# CLK2_STATCOLL3 register map
Vendor: Texas Instruments
Peripheral module from a debugger description file (folder DRA74xP_75xP_76xP_77xP).
Registers are 32-bit, access per field, reset 0x0 unless marked. A register's access mark holds for its fields unless they carry their own. Offsets are as the file gives them; lines under a group give offsets from that group; [hi:lo] are bit positions; {n}, {i} and the like mark numbered series; 'fields as' and 'values as' point back to an identical list; <NAME> marks a mode.

## CLK2_STATCOLL3
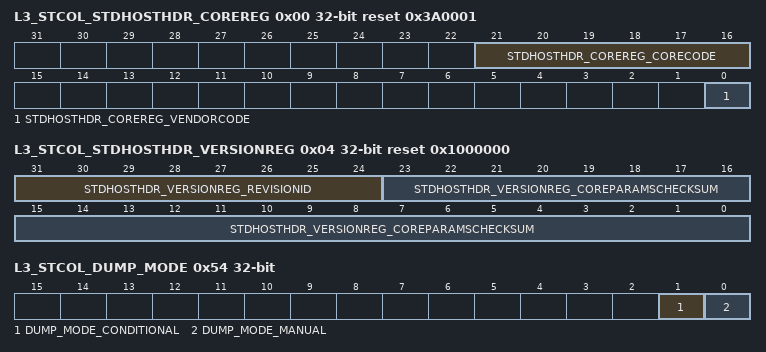
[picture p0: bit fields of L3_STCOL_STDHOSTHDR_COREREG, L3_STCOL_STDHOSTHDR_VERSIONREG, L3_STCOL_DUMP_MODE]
0x00 L3_STCOL_STDHOSTHDR_COREREG access not given reset 0x3A0001
  [21:16] STDHOSTHDR_COREREG_CORECODE ro — The Core Code field is a constant reporting a vendor-specific core generator code. Type: Constant. Reset value: 0x3A. (When the instance is CLK3_FLAGMUX_STATCOLL reset value is 0x37)
  [0] STDHOSTHDR_COREREG_VENDORCODE — The Vendor Code field is a constant reporting the core generator vendor code. Type: Constant. Reset value: 0x1. (access R1)
    0=Third-party_vendor; 1=STDHOSTHDR_COREREG_VENDORCODE_1_r
0x04 L3_STCOL_STDHOSTHDR_VERSIONREG ro reset 0x1000000
  [31:24] STDHOSTHDR_VERSIONREG_REVISIONID — The Revision Identifier field is a constant reporting the core generator revision number. Type: Constant. Reset value: 0x1.
  [23:0] STDHOSTHDR_VERSIONREG_COREPARAMSCHECKSUM — Reserved. Type: Reserved. Reset value: Reserved.
0x08 L3_STCOL_EN
  [0] EN rw — Enable performance monitoring, this will also shut down the clock if En = 0 Type: Control. Reset value: 0x0.
0x0C L3_STCOL_SOFTEN
  [0] SOFTEN rw — Software enable for performance monitoring Type: Control. Reset value: 0x0.
0x10 L3_STCOL_IGNORESUSPEND
  [0] IGNORESUSPEND rw — Ignore suspend if set to one for suspend mechanism Type: Control. Reset value: 0x0.
0x14 L3_STCOL_TRIGEN
  [0] TRIGEN rw — TrigEn when set, it enable the external trigger start and stop Type: Control. Reset value: 0x0.
0x18 L3_STCOL_REQEVT
  [3:0] REQEVT rw — Req event select Type: Control. Reset value: 0x0.
    0=disabled (Collect is disabled default value); 1=all events (Collect all event: hit always (cycle)); 2=transfers (Collect transfers: actually used cycle for transferring aN NTTP word); 3=wayt cycle (Collect wait cycle: transfer has been delayed by source); 4=busy (Collect busy: transfer has been delayed by destination); 5=packet (Collect packet: new packet start); 6=data (Collect data: data cycle transfer, write for requests, read for responses); 7=idles (Collect idles: transfer is not initiated by source); 8=latency (Collect latency: hit when actually detecting debug bit on response links)
0x1C L3_STCOL_RSPEVT
  [3:0] RSPEVT rw — Rsp event select Type: Control. Reset value: 0x0.
    0=disabled (Collect is disabled default value); 1=Collect_all_event:_hit_always_(cycle); 2=Collect transfers: actually used cycle for transferring a NTTP word; 3=Collect wait cycle: transfer has been delayed by source; 4=Collect busy: transfer has been delayed by destination; 5=Collect packet: new packet start; 6=Collect data: data cycle transfer, write for requests, read for responses; 7=Collect idles: transfer is not initiated by source; 8=Collect latency: hit when actually detecting debug bit on response links
{0x20+4i} L3_STCOL_EVTMUX_SEL{i} (i=0..7)
  [2:0] EVTMUX_SEL{i} rw — The select of the mux {i} Type: Control. Reset value: 0x0.
0x40 L3_STCOL_DUMP_IDENTIFIER ro
  [3:0] DUMP_IDENTIFIER — Probe identifier Type: Control. Reset value: 0x0.
0x44 L3_STCOL_DUMP_COLLECTTIME rw
  [31:0] DUMP_COLLECTTIME — Number of cycle to wait between two statistics frame Type: Control. Reset value: 0x0.
0x48 L3_STCOL_DUMP_SLVADDR ro reset 0x19
  [6:0] DUMP_SLVADDR — Dump slave address Type: Control. Reset value: 0x19.
0x4C L3_STCOL_DUMP_MSTADDR ro (reset mask 0xFFFFFF00)
  [7:0] DUMP_MSTADDR — Dump master address Type: Control. Reset value: 0xE0.
0x50 L3_STCOL_DUMP_SLVOFS rw reset 0x800
  [31:0] DUMP_SLVOFS — Dump slave offset Type: Control. Reset value: 0x800.
0x54 L3_STCOL_DUMP_MODE
  [1] DUMP_MODE_CONDITIONAL rw — Define the stat conditional dump, if one a dump will be generated when alarm is trigged Type: Control. Reset value: 0x0.
  [0] DUMP_MODE_MANUAL rw — Define the dump mode: if != 0 the dump is controlled by the Send register. Type: Control. Reset value: 0x0.
0x58 L3_STCOL_DUMP_SEND
  [0] DUMP_SEND rw — In manual mode, is used to send the dump content and initialize the counters. Type: Give_AutoCleared. Reset value: 0x0.
0x5C L3_STCOL_DUMP_DISABLE
  [0] DUMP_DISABLE rw — If 1, the dump frame will be disabled, but counters still active.This is typically used when counters monitoring is enabled Type: Control. Reset value: 0x0.
0x60 L3_STCOL_DUMP_ALARM_TRIG
  [0] DUMP_ALARM_TRIG rw — In Alarm Mode, is used to reset Alarm Type: Take. Reset value: 0x0.
0x64 L3_STCOL_DUMP_ALARM_MINVAL rw
  [31:0] DUMP_ALARM_MINVAL — In Alarm Mode, used to trig an alert if any of counter value is less than AlarmMinVal Type: Control. Reset value: 0x0.
0x68 L3_STCOL_DUMP_ALARM_MAXVAL rw
  [31:0] DUMP_ALARM_MAXVAL — In Alarm Mode, used to trig an alert if any of counter value is larger or equal to AlarmMaxVal Type: Control. Reset value: 0x0.
{0x6C+4i} L3_STCOL_DUMP_ALARM_MODE{i} (i=0..6)
  [1:0] DUMP_ALARM_MODE{i} rw — Alarm Mode off/min/max/both Type: Control. Reset value: 0x0.
    0=OFF; 1=MIN; 3=MIN_MAX (MAX); 2=MAX (BOTH)
0x88 L3_STCOL_DUMP_ALARM_MODE7
  [1:0] DUMP_ALARM_MODE7 rw — Alarm Mode off/min/max/both Type: Control. Reset value: 0x0.
    0=OFF; 1=MIN; 3=MIN_MAX; 2=MAX
{0x8C+4i} L3_STCOL_DUMP_CNT{i} ro (i=0..5)
  [31:0] DUMP_CNT{i} — Dump counter value Type: Status. Reset value: X.
0xA4 L3_STCOL_DUMP_CNT6 ro reset not defined
  [31:0] DUMP_CNT6 — Dump counter value Type: Status. Reset value: X.
0xA8 L3_STCOL_DUMP_CNT7 ro reset not defined
  [31:0] DUMP_CNT7 — Dump counter value Type: Status. Reset value: X.
{0xAC+0x158*i} L3_STCOL_FILTER_i_GLOBALEN_{i} (i=0..7)
  [0] FILTER_i_GLOBALEN rw — Filter global enable Type: Control. Reset value: 0x0.
{0xB0+0x158*i} L3_STCOL_FILTER_i_ADDRMIN_{i} (i=0..7)
  [22:0] FILTER0_ADDRMIN rw — Min addr range Type: Control. Reset value: 0x0.
{0xB4+0x158*i} L3_STCOL_FILTER_i_ADDRMAX_{i} (i=0..7)
  [22:0] FILTER0_ADDRMAX rw — Max addr range Type: Control. Reset value: 0x0.
{0xB8+0x158*i} L3_STCOL_FILTER_i_ADDREN_{i} (i=0..7)
  [0] FILTER0_ADDREN rw — max filtering enable Type: Control. Reset value: 0x0.
{0xBC+0x158*i} L3_STCOL_FILTER_i_EN_k_{i} (i=0..7)
  [0] FILTER_i_EN0 rw — Enable filter stage 0 Type: Control. Reset value: 0x0.
{0xC0+0x158*i} L3_STCOL_FILTER_i_MASK_m_RD_{i} (i=0..7)
  [0] FILTER_i_MASK_m_RD rw — Mask/Match of Rd Type: Control. Reset value: 0x0.
{0xC4+0x158*i} L3_STCOL_FILTER_i_MASK_m_WR_{i} (i=0..7)
  [0] FILTER_i_MASK_m_WR rw — Mask/Match of Wr Type: Control. Reset value: 0x0.
{0xC8+0x158*i} L3_STCOL_FILTER_i_MASK_m_MSTADDR_{i} (i=0..7)
  [7:0] FILTER_i_MASK_m_MSTADDR rw — Mask/Match of MstAddr Type: Control. Reset value: 0x0.
{0xCC+0x158*i} L3_STCOL_FILTER_i_MASK_m_SLVADDR_{i} (i=0..7)
  [6:0] FILTER_i_MASK_m_SLVADDR rw — Mask/Match of SlvAddr Type: Control. Reset value: 0x0.
{0xD0+0x158*i} L3_STCOL_FILTER_i_MASK_m_ERR_{i} (i=0..7)
  [0] FILTER_i_MASK_m_ERR rw — Mask/Match of Err Type: Control. Reset value: 0x0.
{0xD4+0x158*i} L3_STCOL_FILTER_i_MASK_m_REQUSERINFO_{i} (i=0..7)
  [27:0] FILTER_i_MASK_m_REQUSERINFO rw — Mask/Match of ReqUserInfo Type: Control. Reset value: 0x0.
{0xD8+0x158*i} L3_STCOL_FILTER_i_MASK_m_RSPUSERINFO_{i} (i=0..7)
  [2:0] FILTER_i_MASK_m_RSPUSERINFO rw — Mask/Match of RspUserInfo Type: Control. Reset value: 0x0.
{0xE0+0x158*i} L3_STCOL_FILTER_i_MATCH_m_RD_{i} (i=0..7)
  [0] FILTER_i_MATCH_m_RD rw — Mask/Match of Rd Type: Control. Reset value: 0x0.
{0xE4+0x158*i} L3_STCOL_FILTER_i_MATCH_m_WR_{i} (i=0..7)
  [0] FILTER_i_MATCH_m_WR rw — Mask/Match of Wr Type: Control. Reset value: 0x0.
{0xE8+0x158*i} L3_STCOL_FILTER_i_MATCH_m_MSTADDR_{i} (i=0..7)
  [7:0] FILTER_i_MATCH_m_MSTADDR rw — Mask/Match of MstAddr Type: Control. Reset value: 0x0.
{0xEC+0x158*i} L3_STCOL_FILTER_i_MATCH_m_SLVADDR_{i} (i=0..7)
  [4:0] FILTER0_MATCH0_SLVADDR rw — Mask/Match of SlvAddr Type: Control. Reset value: 0x0.
{0xF0+0x158*i} L3_STCOL_FILTER_i_MATCH_m_ERR_{i} (i=0..7)
  [0] FILTER_i_MATCH_m_ERR rw — Mask/Match of Err Type: Control. Reset value: 0x0.
{0xF4+0x158*i} L3_STCOL_FILTER_i_MATCH_m_REQUSERINFO_{i} (i=0..7)
  fields as L3_STCOL_FILTER_i_MASK_m_REQUSERINFO_0
{0xF8+0x158*i} L3_STCOL_FILTER_i_MATCH_m_RSPUSERINFO_{i} (i=0..7)
  fields as L3_STCOL_FILTER_i_MASK_m_RSPUSERINFO_0
{0x1F0+0x158*i} L3_STCOL_OP_i_THRESHOLD_MINVAL_{i} (i=0..7)
  [12:0] OP_i_THRESHOLD_MINVAL rw — Min value Type: Control. Reset value: 0x0.
{0x1F4+0x158*i} L3_STCOL_OP_i_THRESHOLD_MAXVAL_{i} (i=0..7)
  [12:0] OP_i_THRESHOLD_MAXVAL rw — Max value Type: Control. Reset value: 0x0.
{0x1F8+0x158*i} L3_STCOL_OP_i_EVTINFOSEL_{i} (i=0..7)
  [1:0] OP_i_EVTINFOSEL rw — Select event info data to add to counter (len/press or latency) Type: Control. Reset value: 0x0.
    0=Select len from event info list; 1=Select pressure if available from event info list; 2=Select latency if available from event info list
{0x1FC+0x158*i} L3_STCOL_OP_i_SEL_{i} (i=0..7)
  [3:0] OP_i_SEL rw — Select logical operation Type: Control. Reset value: 0x0.
    0=Increment counter on each mask/match filter hit; 1=Increment counter on each min/max level hit; 2=Add to counter the selected event info value (len/press or latency); 3=increment counter when all filter event hits (And(Fi)); 4=Increment counter if any of filter event hits (Or(Fi)); 5=Add to counter the number of current request event that hit; 6=Add to counter the number of current response event that hit; 7=Add to counter the number of all event that hit; 8=Increment counter on each selected external event hit
